# PIC32CX1025SG60100 device description
Architecture: CORTEX-M4; Family: PIC32CX; Series: PIC32CXSG60
Registers are 32-bit, read-write, reset 0x0 unless marked. A register's access mark holds for its fields unless they carry their own. Offsets are from the block's base; [hi:lo] are bit positions; lines under a group give offsets from that group; {n}, {i} and the like mark numbered series.

## EVSYS — Event System Interface
Instances: EVSYS 0x4100E000
0x00 CTRLA 8-bit — Control
  [0] SWRST — Software Reset
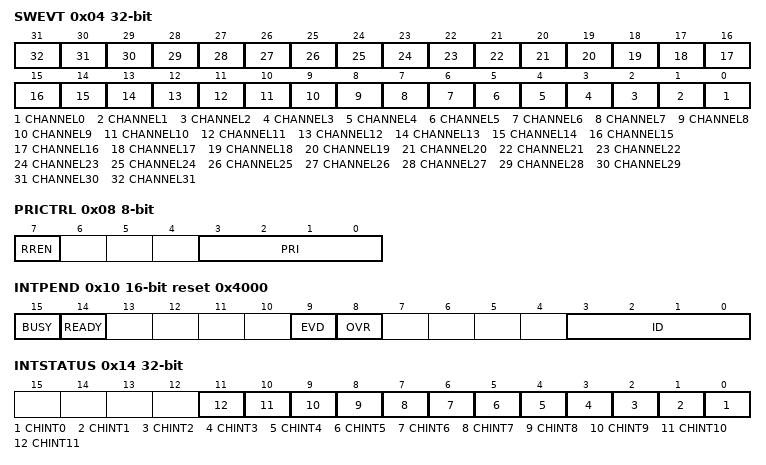
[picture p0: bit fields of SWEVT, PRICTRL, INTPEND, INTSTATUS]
0x04 SWEVT wo — Software Event
  [n] CHANNEL{n} (n=0..31) — Channel {n} Software Selection
0x08 PRICTRL 8-bit — Priority Control
  [7] RREN — Round-Robin Scheduling Enable
  [3:0] PRI — Channel Priority Number
0x10 INTPEND 16-bit reset 0x4000 — Channel Pending Interrupt
  [15] BUSY
  [14] READY
  [9] EVD — Channel Event Detected
  [8] OVR — Channel Overrun
  [3:0] ID — Channel ID
0x14 INTSTATUS ro — Interrupt Status
  [n] CHINT{n} (n=0..11) — Channel {n} Pending Interrupt
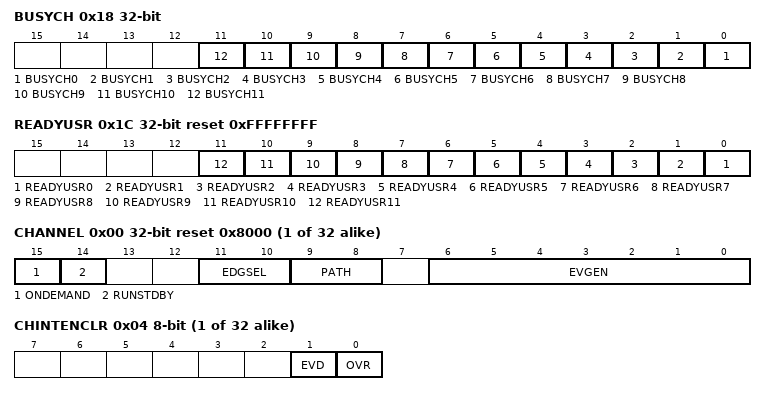
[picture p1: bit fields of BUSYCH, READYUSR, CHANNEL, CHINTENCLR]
0x18 BUSYCH ro — Busy Channels
  [n] BUSYCH{n} (n=0..11) — Busy Channel {n}
0x1C READYUSR ro reset 0xFFFFFFFF — Ready Users
  [n] READYUSR{n} (n=0..11) — Ready User for Channel {n}
{0x20+8i} CHANNEL[{i}] (i=0..31) group
  0x00 CHANNEL reset 0x8000 — Channel n Control
    [15] ONDEMAND — Generic Clock On Demand
    [14] RUNSTDBY — Run in standby
    [11:10] EDGSEL — Edge Detection Selection
      0=NO_EVT_OUTPUT (No event output when using the resynchronized or synchronous path); 1=RISING_EDGE (Event detection only on the rising edge of the signal from the event generator when using the resynchronized or synchronous path); 2=FALLING_EDGE (Event detection only on the falling edge of the signal from the event generator when using the resynchronized or synchronous path); 3=BOTH_EDGES (Event detection on rising and falling edges of the signal from the event generator when using the resynchronized or synchronous path)
    [9:8] PATH — Path Selection
      0=SYNCHRONOUS (Synchronous path); 1=RESYNCHRONIZED (Resynchronized path); 2=ASYNCHRONOUS (Asynchronous path)
    [6:0] EVGEN — Event Generator Selection
  0x04 CHINTENCLR 8-bit (atomic clear) — Channel n Interrupt Enable Clear
    [1] EVD — Channel Event Detected Interrupt Disable
    [0] OVR — Channel Overrun Interrupt Disable
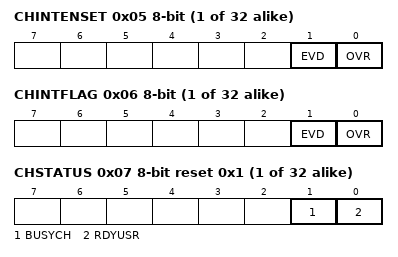
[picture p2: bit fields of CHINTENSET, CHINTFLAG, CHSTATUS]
  0x05 CHINTENSET 8-bit (atomic set) — Channel n Interrupt Enable Set
    [1] EVD — Channel Event Detected Interrupt Enable
    [0] OVR — Channel Overrun Interrupt Enable
  0x06 CHINTFLAG 8-bit (atomic clear) — Channel n Interrupt Flag Status and Clear
    [1] EVD — Channel Event Detected
    [0] OVR — Channel Overrun
  0x07 CHSTATUS 8-bit ro reset 0x1 — Channel n Status
    [1] BUSYCH — Busy Channel
    [0] RDYUSR — Ready User
{0x120+4i} USER[{i}] (i=0..66) — User Multiplexer n
  [5:0] CHANNEL — Channel Event Selection

## FREQM — Frequency Meter
Instances: FREQM 0x40002C00
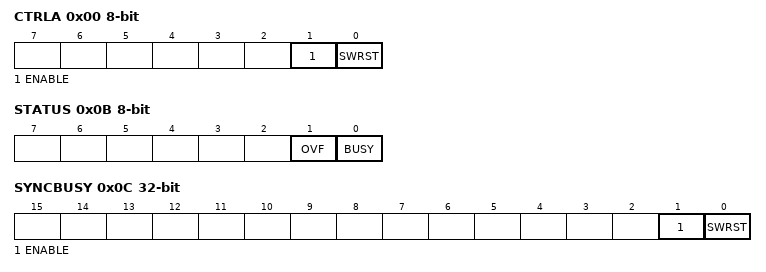
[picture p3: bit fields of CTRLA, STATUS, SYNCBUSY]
0x00 CTRLA 8-bit — Control A Register
  [1] ENABLE
  [0] SWRST — Software Reset
0x01 CTRLB 8-bit wo — Control B Register
  [0] START — Start Measurement
0x02 CFGA 16-bit — Config A register
  [7:0] REFNUM — Number of Reference Clock Cycles
0x08 INTENCLR 8-bit (atomic clear) — Interrupt Enable Clear Register
  [0] DONE — Measurement Done Interrupt Enable
0x09 INTENSET 8-bit (atomic set) — Interrupt Enable Set Register
  [0] DONE — Measurement Done Interrupt Enable
0x0A INTFLAG 8-bit (atomic clear) — Interrupt Flag Register
  [0] DONE — Measurement Done
0x0B STATUS 8-bit
  [1] OVF — Sticky Count Value Overflow
  [0] BUSY — FREQM Status
0x0C SYNCBUSY ro — Synchronization Busy Register
  [1] ENABLE
  [0] SWRST — Software Reset
0x10 VALUE ro — Count Value Register
  [23:0] VALUE — Measurement Value

## GCLK — Generic Clock Generator
Instances: GCLK 0x40001C00
0x00 CTRLA 8-bit (WSYNC) — Control
  [0] SWRST — Software Reset
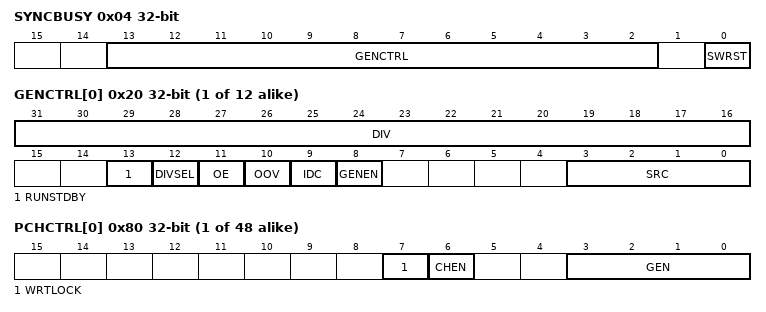
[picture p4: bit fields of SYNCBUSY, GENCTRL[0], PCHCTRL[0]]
0x04 SYNCBUSY ro — Synchronization Busy
  [13:2] GENCTRL — Generic Clock Generator Control n Synchronization Busy bits
    1=GCLK0 (Generic clock generator 0); 2=GCLK1 (Generic clock generator 1); 4=GCLK2 (Generic clock generator 2); 8=GCLK3 (Generic clock generator 3); 16=GCLK4 (Generic clock generator 4); 32=GCLK5 (Generic clock generator 5); 64=GCLK6 (Generic clock generator 6); 128=GCLK7 (Generic clock generator 7); 0x0100=GCLK8 (Generic clock generator 8); 0x0200=GCLK9 (Generic clock generator 9); 0x0400=GCLK10 (Generic clock generator 10); 0x0800=GCLK11 (Generic clock generator 11)
  [0] SWRST — Software Reset Synchroniation Busy bit
{0x20+4i} GENCTRL[{i}] (i=0..11) — Generic Clock Generator Control
  [31:16] DIV — Division Factor
  [13] RUNSTDBY — Run in Standby
  [12] DIVSEL — Divide Selection
    0=DIV1 (Divide input directly by divider factor); 1=DIV2 (Divide input by 2^(divider factor+ 1))
  [11] OE — Output Enable
  [10] OOV — Output Off Value
  [9] IDC — Improve Duty Cycle
  [8] GENEN — Generic Clock Generator Enable
  [3:0] SRC — Source Select
    0=XOSC0 (XOSC0 oscillator output); 1=XOSC1 (XOSC1 oscillator output); 2=GCLKIN (Generator input pad); 3=GCLKGEN1 (Generic clock generator 1 output); 4=OSCULP32K (OSCULP32K oscillator output); 5=XOSC32K (XOSC32K oscillator output); 6=DFLL (DFLL output); 7=DPLL0 (DPLL0 output); 8=DPLL1 (DPLL1 output)
{0x80+4i} PCHCTRL[{i}] (i=0..47) — Peripheral Clock Control
  [7] WRTLOCK — Write Lock
  [6] CHEN — Channel Enable
  [3:0] GEN — Generic Clock Generator
    {v}=GCLK{v} (Generic clock generator {v}) (v=0..11)

## Notices in the file
Copyright (c) 2021 Microchip Technology Inc.
SPDX-License-Identifier: Apache-2.0
Licensed under the Apache License, Version 2.0 (the "License");
you may not use this file except in compliance with the License.
You may obtain a copy of the License at
http://www.apache.org/licenses/LICENSE-2.0
Unless required by applicable law or agreed to in writing, software
distributed under the License is distributed on an "AS IS" BASIS,
WITHOUT WARRANTIES OR CONDITIONS OF ANY KIND, either express or implied.
See the License for the specific language governing permissions and
limitations under the License.
